VERSION "1"

NS_ :

BS_:

BU_: ECU HOST_PC

BO_ 272 Throttle_Command: 2 HOST_PC
 SG_ THROTTLE_PEDAL_EN_CTRL : 0|8@1+ (1,0) [0|1] ""  ECU
 SG_ THROTTLE_PEDAL_CMD : 8|8@1+ (1,0) [0|100] "%"  ECU

BO_ 273 Brake_Command: 2 HOST_PC
 SG_ BRAKE_PEDAL_EN_CTRL : 0|8@1+ (1,0) [0|1] ""  ECU
 SG_ BRAKE_PEDAL_CMD : 8|8@1+ (1,0) [0|100] "%"  ECU

BO_ 274 Steer_Command: 3 HOST_PC
 SG_ STEER_ANGLE_EN_CTRL : 0|8@1+ (1,0) [0|1] ""  ECU
 SG_ STEER_ANGLE_CMD : 8|16@1- (0.001,0) [-0.524|0.524] "radian"  ECU

BO_ 275 Turnsignal_Command: 1 HOST_PC
 SG_ TURN_SIGNAL_CMD : 0|8@1+ (1,0) [0|2] ""  ECU

BO_ 276 Gear_Command: 1 HOST_PC
 SG_ GEAR_CMD : 0|8@1+ (1,0) [1|4] ""  ECU

BO_ 277 Control_Command: 1 HOST_PC
 SG_ CTRL_CMD : 0|8@1+ (1,0) [0|1] ""  ECU

BO_ 1296 Throttle_Status_: 2 ECU
 SG_ THROTTLE_PEDAL_EN_STS : 0|8@1+ (1,0) [0|1] ""  HOST_PC
 SG_ THROTTLE_PEDAL_STS : 8|8@1+ (1,0) [0|100] "%"  HOST_PC

BO_ 1297 Brake_Status_: 2 ECU
 SG_ BRAKE_PEDAL_EN_STS : 0|8@1+ (1,0) [0|1] ""  HOST_PC
 SG_ BRAKE_PEDAL_STS : 8|8@1+ (1,0) [0|100] "%"  HOST_PC

BO_ 1298 Steer_Status_: 3 ECU
 SG_ STEER_ANGLE_EN_STS : 0|8@1+ (1,0) [0|1] ""  HOST_PC
 SG_ STEER_ANGLE_STS : 8|16@1- (0.001,0) [-0.524|0.524] "radian"  HOST_PC

BO_ 1299 Turnsignal_Status_: 1 ECU
 SG_ TURN_SIGNAL_STS : 0|8@1+ (1,0) [0|2] ""  HOST_PC

BO_ 1300 Gear_Status: 1 ECU
 SG_ GEAR_STS : 0|8@1+ (1,0) [1|4] ""  HOST_PC

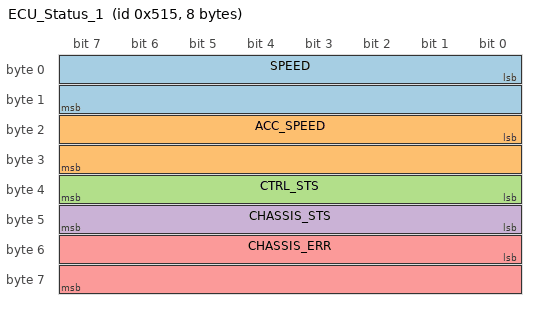
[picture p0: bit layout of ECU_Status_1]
BO_ 1301 ECU_Status_1: 8 ECU
 SG_ SPEED : 0|16@1- (0.01,0) [0|0] "m/s"  HOST_PC
 SG_ ACC_SPEED : 16|16@1- (0.001,0) [0|0] "m/s^2"  HOST_PC
 SG_ CTRL_STS : 32|8@1+ (1,0) [0|1] ""  HOST_PC
 SG_ CHASSIS_STS : 40|8@1+ (1,0) [0|255] ""  HOST_PC
 SG_ CHASSIS_ERR : 48|16@1+ (1,0) [0|65535] ""  HOST_PC
